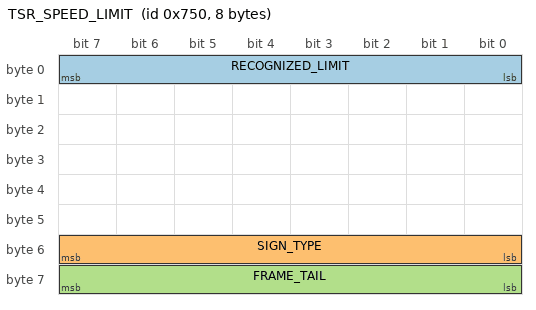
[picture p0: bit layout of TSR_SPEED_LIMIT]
BO_ 1872 TSR_SPEED_LIMIT: 8 CAM
 SG_ RECOGNIZED_LIMIT : 7|8@0+ (1,0) [0|255] "kph" XXX
 SG_ SIGN_TYPE : 55|8@0+ (1,0) [0|255] "" XXX
 SG_ FRAME_TAIL : 63|8@0+ (1,0) [0|255] "" XXX

CM_ BO_ 1872 "EU Honda camera TSR at 50 Hz on ACC-CAN camera side (0x750); not used on US Bosch CAN";
CM_ SG_ 862 SPEED_LIMIT_SIGN "On EU Honda e, use CAMERA_MESSAGES from ACC-CAN camera (bus 2) for sign TSR; PT-side copies can include nav/GPS fused limits";
CM_ SG_ 1872 RECOGNIZED_LIMIT "Posted speed in km/h from camera sign recognition; 0 = no sign";
CM_ SG_ 1872 SIGN_TYPE "Sign subtype / extra code; meaning unknown";

VAL_ 1872 RECOGNIZED_LIMIT 0 "NO_SIGN" 30 "SPEED_LIMIT_30" 50 "SPEED_LIMIT_50" 60 "SPEED_LIMIT_60" 80 "SPEED_LIMIT_80" 100 "SPEED_LIMIT_100";
VAL_ 862 SPEED_LIMIT_SIGN 0 "NO_SIGN" 3 "SPEED_LIMIT_30" 5 "SPEED_LIMIT_50" 6 "SPEED_LIMIT_60" 8 "SPEED_LIMIT_80" 10 "SPEED_LIMIT_100" 17 "SPEED_LIMIT_ZONE_END" 61 "SPEED_LIMIT_NA";
